# GD32F50x register map
File version: 1.0
CPU: CM33 r2p1, little endian, MPU, FPU, 4 interrupt priority bits
Registers are 32-bit, read-write, reset 0x0 unless marked. A register's access mark holds for its fields unless they carry their own. Offsets are from the block's base; [hi:lo] are bit positions.

## USART0 — Universal synchronous asynchronous receiver transmitter
Base 0x40013800
Same registers: USART1 0x40004400, USART2 0x40004800
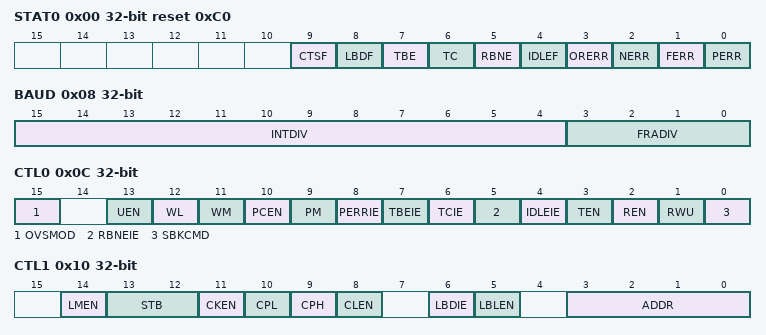
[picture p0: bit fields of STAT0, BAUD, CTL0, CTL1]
0x00 STAT0 ro reset 0xC0 — Status register 0
  [9] CTSF — CTS change flag
  [8] LBDF — LIN break detection flag
  [7] TBE — Transmit data buffer empty
  [6] TC — Transmission complete
  [5] RBNE — Read data buffer not empty
  [4] IDLEF — IDLE frame detected flag
  [3] ORERR — Overrun error
  [2] NERR — Noise error flag
  [1] FERR — Frame error flag
  [0] PERR — Parity error flag
0x04 DATA
  [8:0] DATA — Transmit or read data value
0x08 BAUD — Baud rate register
  [15:4] INTDIV — Integer part of baud-rate divider
  [3:0] FRADIV — Fraction part of baud-rate divider
0x0C CTL0 — Control register 0
  [15] OVSMOD — Oversample mode
  [13] UEN — USART enable
  [12] WL — Word length
  [11] WM — Wakeup method in mute mode
  [10] PCEN — Parity check function enable
  [9] PM — Parity mode
  [8] PERRIE — Parity error interrupt enable
  [7] TBEIE — Transmitter buffer empty interrupt enable
  [6] TCIE — Transmission complete interrupt enable
  [5] RBNEIE — Read data buffer not empty interrupt and overrun error interrupt enable
  [4] IDLEIE — IDLE line detected interrupt enable
  [3] TEN — Transmitter enable
  [2] REN — Receiver enable
  [1] RWU — Receiver wakeup from mute mode
  [0] SBKCMD — Send break command
0x10 CTL1 — Control register 1
  [14] LMEN — LIN mode enable
  [13:12] STB — STOP bits length
  [11] CKEN — CK pin enable
  [10] CPL — Clock polarity
  [9] CPH — Clock phase
  [8] CLEN — CK Length
  [6] LBDIE — LIN break detection interrupt enable
  [5] LBLEN — LIN break frame length
  [3:0] ADDR — Address of the USART
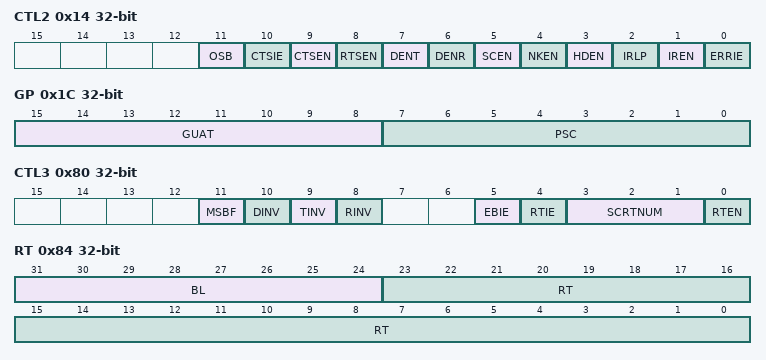
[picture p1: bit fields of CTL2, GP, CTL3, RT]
0x14 CTL2 — Control register 2
  [11] OSB — One sample bit method
  [10] CTSIE — CTS interrupt enable
  [9] CTSEN — CTS enable
  [8] RTSEN — RTS enable
  [7] DENT — DMA request enable for transmission
  [6] DENR — DMA request enable for reception
  [5] SCEN — Smartcard mode enable
  [4] NKEN — Smartcard NACK enable
  [3] HDEN — Half-duplex selection
  [2] IRLP — IrDA low-power
  [1] IREN — IrDA mode enable
  [0] ERRIE — Error interrupt enable
0x1C GP — Guard time and prescaler register
  [15:8] GUAT — Guard time value in Smartcard mode
  [7:0] PSC — Prescaler value
0x80 CTL3 — Control register 3
  [11] MSBF — Most significant bit first
  [10] DINV — Data bit level inversion
  [9] TINV — TX pin level inversion
  [8] RINV — RX pin level inversion
  [5] EBIE — Interrupt enable bit of end of block event
  [4] RTIE — Interrupt enable bit of receive timeout event
  [3:1] SCRTNUM — Smartcard auto-retry number
  [0] RTEN — Receiver timeout enable
0x84 RT — Receiver timeout register
  [31:24] BL — Block Length
  [23:0] RT — Receiver timeout threshold
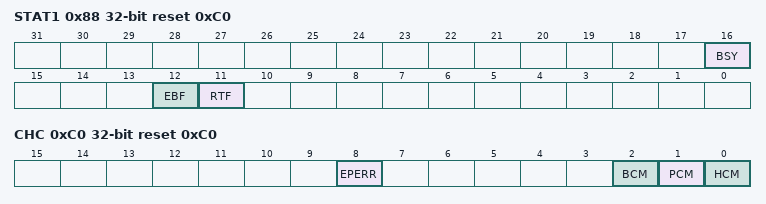
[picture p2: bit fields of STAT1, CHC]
0x88 STAT1 access per field reset 0xC0 — Status register 1
  [16] BSY ro — Busy flag
  [12] EBF wo — End of block flag
  [11] RTF wo — Receiver timeout flag
0xC0 CHC reset 0xC0 — Coherence control register
  [8] EPERR — Early parity error flag
  [2] BCM — Break frame coherence mode
  [1] PCM — Parity check coherence mode
  [0] HCM — Hardware flow control coherence mode

## UART3 — Universal asynchronous receiver transmitter
Base 0x40004C00
Same registers: UART4 0x40005000
Registers as USART0, without CTL3, RT, STAT1; these are added or differ:
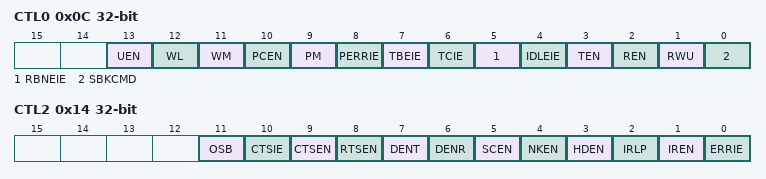
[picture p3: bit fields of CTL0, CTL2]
0x0C CTL0 — Control register 0
  [13] UEN — USART enable
  [12] WL — Word length
  [11] WM — Wakeup method in mute mode
  [10] PCEN — Parity check function enable
  [9] PM — Parity mode
  [8] PERRIE — Parity error interrupt enable
  [7] TBEIE — Transmitter buffer empty interrupt enable
  [6] TCIE — Transmission complete interrupt enable
  [5] RBNEIE — Read data buffer not empty interrupt and overrun error interrupt enable
  [4] IDLEIE — IDLE line detected interrupt enable
  [3] TEN — Transmitter enable
  [2] REN — Receiver enable
  [1] RWU — Receiver wakeup from mute mode
  [0] SBKCMD — Send break command
0x14 CTL2 — Control register 2
  [11] OSB — One sample bit method enable
  [10] CTSIE — CTS interrupt enable
  [9] CTSEN — CTS enable
  [8] RTSEN — RTS enable
  [7] DENT — DMA request enable for transmission
  [6] DENR — DMA request enable for reception
  [5] SCEN — Smartcard mode enable
  [4] NKEN — Smartcard NACK enable
  [3] HDEN — Half-duplex selection
  [2] IRLP — IrDA low-power
  [1] IREN — IrDA mode enable
  [0] ERRIE — Error interrupt enable
